# Cortex_M0+ register map
Vendor: ARM Ltd.; Series: M; File version: 2020-08-22T15:13:24.354567-05:00
CPU: CM4 r0p0, little endian, vendor SysTick, 8 interrupt priority bits
Registers are 32-bit, read-write, no defined reset value unless marked. A register's access mark holds for its fields unless they carry their own. Offsets are from the block's base; [hi:lo] are bit positions; lines under a group give offsets from that group; {n}, {i} and the like mark numbered series.

## ID — ID registers
Base 0xE000ED00
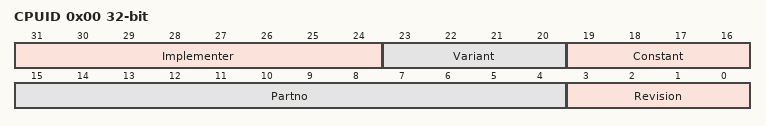
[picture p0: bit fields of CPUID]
0x00 CPUID ro — Contains the part number, version, and implementation information that is specific to this processor
  [31:24] Implementer — Implementer code
  [23:20] Variant — Implementation defined
  [19:16] Constant — Indicates the architecture
  [15:4] Partno — Indicates part number
  [3:0] Revision — Indicates revision

## MPU — Memory Protection Unit registers
Base 0xE000ED90
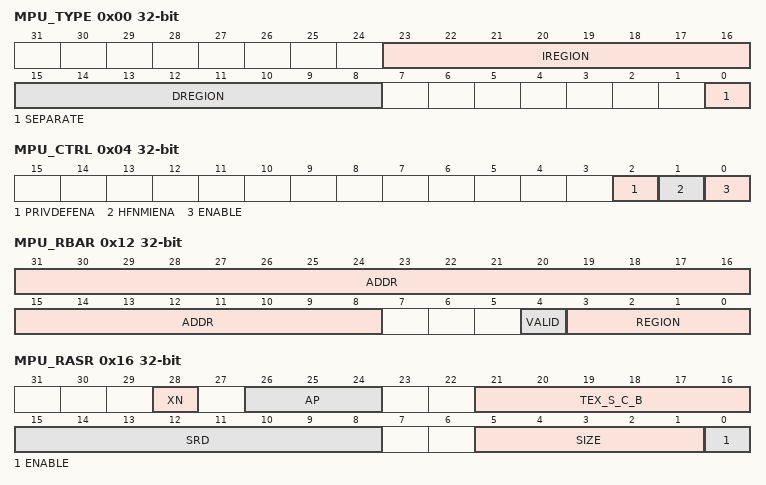
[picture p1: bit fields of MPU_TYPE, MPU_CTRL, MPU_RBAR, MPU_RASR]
0x00 MPU_TYPE ro — The MPU Type Register indicates how many regions the MPU supports
  [23:16] IREGION — Instruction region, not supported
  [15:8] DREGION — Number of regions supported by the MPU
  [0] SEPARATE — Indicates support for separate instruction and data address maps
0x04 MPU_CTRL — Enables the MPU, and when the MPU is enabled, controls whether the default memory map is enabled as a background region for privileged accesses, and whether the MPU is enabled for HardFaults and NMIs
  [all] fields
    0=Disabled; 1=Enabled
  [2] PRIVDEFENA — Privileged default memory map enable (when ENABLE = 1)
  [1] HFNMIENA — MPU HardFault and NMI enable (when ENABLE = 1)
  [0] ENABLE — Enables the MPU
0x08 MPU_RNR — Selects the region currently accessed by MPU_RBAR and MPU_RASR
  [7:0] REGION — Indicates the memory region accessed by MPU_RBAR and MPU_RASR
0x12 MPU_RBAR — Holds the base address of the region identified by MPU_RNR
  [31:8] ADDR — Base address of the region
  [4] VALID — On writes to the register, indicates whether the write must update the base address of the region identified by the REGION field
  [3:0] REGION — On writes, can specify the number of the region to update, on reads, returns bits [3:0] of MPU_RNR
0x16 MPU_RASR — Defines the size, access behavior, and memory type of the region identified by MPU_RNR, and enables that region
  [28] XN — Execute Never - Indicates whether the processor can execute instructions from the region
    0=Execution_permitted; 1=Execution_not_permitted
  [26:24] AP — Access and privilege properties of the region
    0=No_access; 1=Privileged_RW; 2=Privileged_RW_Unprivileged_RO; 3=Full_access; 5=Privileged_RO; 6=Privileged_RO_Unprivileged_RO; 7=Privileged_RO_Unprivileged_RO
  [21:16] TEX_S_C_B — Memory type, cacheable and shareable properties of the region
    0=Strongly_ordered_Shareable; 1=Shared_device; 2=Outer_inner_write_through_No_write_allocate_Not_shareable; 3=Outer_inner_write_back_No_write_allocate_Not_shareable; 4=Strongly_ordered_Shareable_; 5=Shared_device_; 6=Outer_inner_write_through_No_write_allocate_Shareable; 7=Outer_inner_write_back_No_write_allocate_Shareable
  [15:8] SRD — Subregion Disable
  [5:1] SIZE — Indicates the region size
    7=_256B; 8=_512B; 9=_1KB; 10=_2KB; 11=_4KB; 12=_8KB; 13=_16KB; 14=_32KB; 15=_64KB; 16=_128KB; 17=_256KB; 18=_512KB; 19=_1MB; 20=_2MB; 21=_4MB; 22=_8MB; 23=_16MB; 24=_32MB; 25=_64MB; 26=_128MB; 27=_256MB; 28=_512MB; 29=_1GB; 30=_2GB; 31=_4GB
  [0] ENABLE — Enables this region (when the MPU is enabled)
    0=Disabled; 1=Enabled

## NVIC — Nested Vectored Interrupt Controller registers
Base 0xE000E100
0x00 NVIC_ISER0 — Enables, or reads the enable state of a group of interrupts
0x128 NVIC_ICER0 — Disables, or reads the enable state of a group of interrupts
0x256 NVIC_ISPR0 — For a group of interrupts, changes interrupt status to pending, or shows the current pending status
0x384 NVIC_ICPR0 — For a group of interrupts, clears the interrupt pending status, or shows the current pending status
0x512 NVIC_IABR0 — For a group of 32 interrupts, shows whether each interrupt is active
0x768 NVIC_IPR0 — Sets or reads interrupt priorities
0x772 NVIC_IPR1 — Sets or reads interrupt priorities
0x776 NVIC_IPR2 — Sets or reads interrupt priorities
{0x774+4i} NVIC_IPR{i} (i=3..5) — Sets or reads interrupt priorities
0x792 NVIC_IPR6 — Sets or reads interrupt priorities
0x796 NVIC_IPR7 — Sets or reads interrupt priorities
